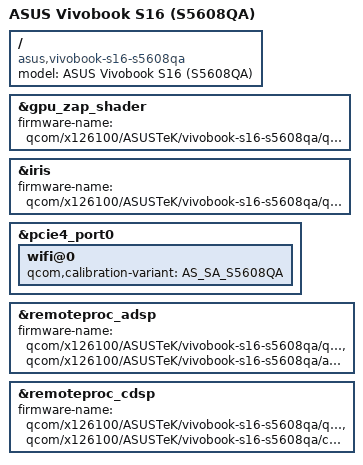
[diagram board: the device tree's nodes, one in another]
// SPDX-License-Identifier: BSD-3-Clause
/*
 * ASUS Vivobook S16 (S5608QA), Snapdragon X X1-26-101.
 *
 * BIOS S5608QA.304, DSDT SKU "S56". The board is described in
 * x126100-asus-vivobook-s5x08.dtsi.
 */

#include "x126100-asus-vivobook-s5x08.dtsi"

/ {
	model = "ASUS Vivobook S16 (S5608QA)";
	compatible = "asus,vivobook-s16-s5608qa", "qcom,x126100", "qcom,x1p42100";
};

&gpu_zap_shader {
	firmware-name = "qcom/x126100/ASUSTeK/vivobook-s16-s5608qa/qcdxkmsucpurwa.mbn";
};

&iris {
	firmware-name = "qcom/x126100/ASUSTeK/vivobook-s16-s5608qa/qcvss8380.mbn";
};

/* The BIOS's SMBIOS board data name is BDF_AS_SA_S5608QA */
&pcie4_port0 {
	wifi@0 {
		qcom,calibration-variant = "AS_SA_S5608QA";
	};
};

&remoteproc_adsp {
	firmware-name = "qcom/x126100/ASUSTeK/vivobook-s16-s5608qa/qcadsp8380.mbn",
			"qcom/x126100/ASUSTeK/vivobook-s16-s5608qa/adsp_dtbs.elf";
};

&remoteproc_cdsp {
	firmware-name = "qcom/x126100/ASUSTeK/vivobook-s16-s5608qa/qccdsp8380.mbn",
			"qcom/x126100/ASUSTeK/vivobook-s16-s5608qa/cdsp_dtbs.elf";
};
